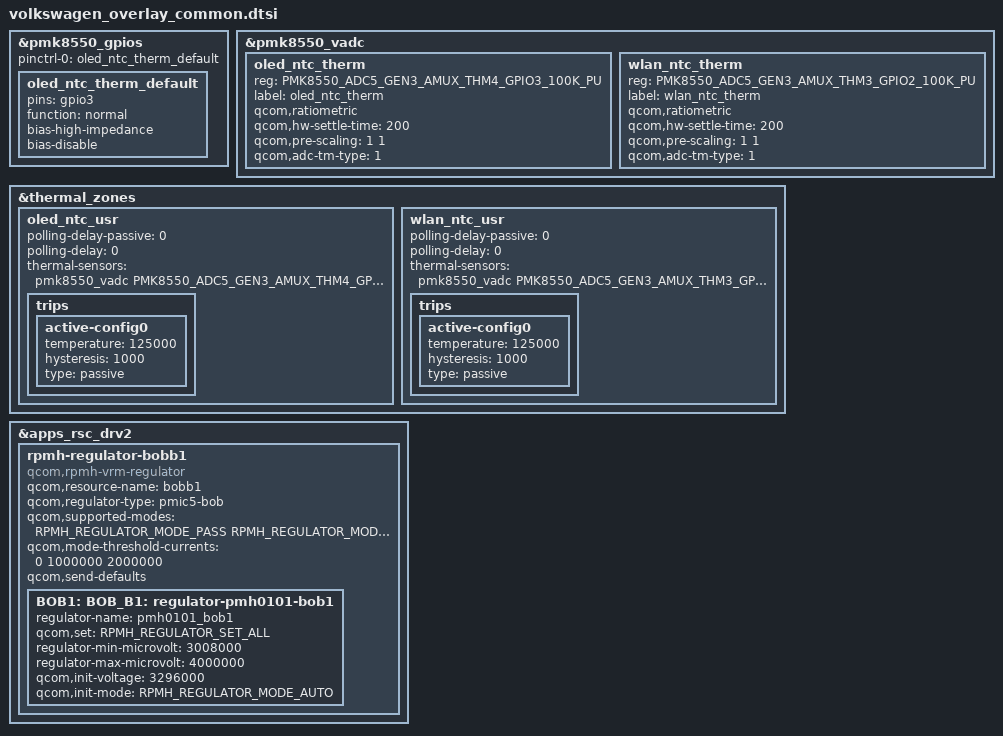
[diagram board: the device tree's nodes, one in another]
#include <dt-bindings/iio/qcom,spmi-adc5-gen3-pmk8550.h>
#include <dt-bindings/regulator/qcom,rpmh-regulator-levels.h>

&pmk8550_gpios {
	pinctrl-0 = <&oled_ntc_therm_default>;
	pinctrl-names = "default";
	oled_ntc_therm_default: oled_ntc_therm_default {
		pins = "gpio3";
		function = "normal";
		bias-high-impedance;
		bias-disable;
	};
};

&pmk8550_vadc {
	oled_ntc_therm {
		reg = <PMK8550_ADC5_GEN3_AMUX_THM4_GPIO3_100K_PU>;
		label = "oled_ntc_therm";
		qcom,ratiometric;
		qcom,hw-settle-time = <200>;
		qcom,pre-scaling = <1 1>;
		qcom,adc-tm-type = <1>;
	};
	wlan_ntc_therm {
		reg = <PMK8550_ADC5_GEN3_AMUX_THM3_GPIO2_100K_PU>;
		label = "wlan_ntc_therm";
		qcom,ratiometric;
		qcom,hw-settle-time = <200>;
		qcom,pre-scaling = <1 1>;
		qcom,adc-tm-type = <1>;
	};
};
&thermal_zones {
	oled_ntc_usr {
		polling-delay-passive = <0>;
		polling-delay = <0>;
		thermal-sensors = <&pmk8550_vadc PMK8550_ADC5_GEN3_AMUX_THM4_GPIO3_100K_PU>;
		trips {
			active-config0 {
				temperature = <125000>;
				hysteresis = <1000>;
				type = "passive";
			};
		};
	};
	wlan_ntc_usr {
		polling-delay-passive = <0>;
		polling-delay = <0>;
		thermal-sensors = <&pmk8550_vadc PMK8550_ADC5_GEN3_AMUX_THM3_GPIO2_100K_PU>;
		trips {
			active-config0 {
				temperature = <125000>;
				hysteresis = <1000>;
				type = "passive";
			};
		};
	};
};

&apps_rsc_drv2 {
	rpmh-regulator-bobb1 {
		compatible = "qcom,rpmh-vrm-regulator";
		qcom,resource-name = "bobb1";
		qcom,regulator-type = "pmic5-bob";
        qcom,supported-modes =
            <RPMH_REGULATOR_MODE_PASS
             RPMH_REGULATOR_MODE_AUTO
             RPMH_REGULATOR_MODE_HPM>;
        qcom,mode-threshold-currents = <0 1000000 2000000>;
        qcom,send-defaults;

		BOB1: BOB_B1: pmh0101_bob1: regulator-pmh0101-bob1 {
			regulator-name = "pmh0101_bob1";
			qcom,set = <RPMH_REGULATOR_SET_ALL>;
			regulator-min-microvolt = <3008000>;
			regulator-max-microvolt = <4000000>;
			qcom,init-voltage = <3296000>;
			qcom,init-mode = <RPMH_REGULATOR_MODE_AUTO>;
		};
	};
};
